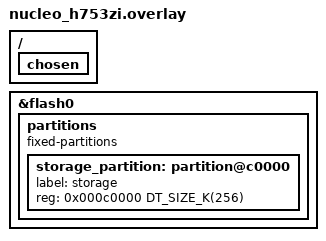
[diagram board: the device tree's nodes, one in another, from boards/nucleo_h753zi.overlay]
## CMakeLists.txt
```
# SPDX-License-Identifier: Apache-2.0 Copyright 2026 Migris Labs

cmake_minimum_required(VERSION 3.20.0)

find_package(Zephyr REQUIRED HINTS $ENV{ZEPHYR_BASE})
project(fsw_core_tc_uart LANGUAGES C)

# Pull in the freestanding PUS codec from lib/pus/. Same translation units the host C++ build links
# into migris::fsw-core — keeping the wire-format bytes identical between flight and host tests is
# the whole point of the layout.
set(MIGRIS_FSW_PUS_DIR ${CMAKE_CURRENT_SOURCE_DIR}/../../lib/pus)
set(MIGRIS_FSW_FDIR_DIR ${CMAKE_CURRENT_SOURCE_DIR}/../../lib/fdir)
set(MIGRIS_FSW_DATAPOOL_DIR ${CMAKE_CURRENT_SOURCE_DIR}/../../lib/datapool)
set(MIGRIS_FSW_SCHEDULE_DIR ${CMAKE_CURRENT_SOURCE_DIR}/../../lib/schedule)
set(MIGRIS_FSW_HKSTORE_DIR ${CMAKE_CURRENT_SOURCE_DIR}/../../lib/hkstore)
set(MIGRIS_FSW_PKTSTORE_DIR ${CMAKE_CURRENT_SOURCE_DIR}/../../lib/pktstore)
set(MIGRIS_FSW_LARGEDATA_DIR ${CMAKE_CURRENT_SOURCE_DIR}/../../lib/largedata)
set(MIGRIS_FSW_MODE_DIR ${CMAKE_CURRENT_SOURCE_DIR}/../../lib/mode)
set(MIGRIS_FSW_NVSTORE_DIR ${CMAKE_CURRENT_SOURCE_DIR}/../../lib/nvstore)

target_sources(
  app
  PRIVATE src/main.c
          src/nv_flash_backend.c
          ${MIGRIS_FSW_PUS_DIR}/src/ccsds.c
          ${MIGRIS_FSW_PUS_DIR}/src/pus_tc.c
          ${MIGRIS_FSW_PUS_DIR}/src/pus_tm.c
          ${MIGRIS_FSW_PUS_DIR}/src/pus1.c
          ${MIGRIS_FSW_PUS_DIR}/src/pus5.c
          ${MIGRIS_FSW_PUS_DIR}/src/pus17.c
          ${MIGRIS_FSW_PUS_DIR}/src/pus3.c
          ${MIGRIS_FSW_PUS_DIR}/src/pus11.c
          ${MIGRIS_FSW_PUS_DIR}/src/pus15.c
          ${MIGRIS_FSW_PUS_DIR}/src/pus20.c
          ${MIGRIS_FSW_PUS_DIR}/src/pus13.c
          ${MIGRIS_FSW_PUS_DIR}/src/tc_router.c
          ${MIGRIS_FSW_FDIR_DIR}/src/event_fifo.c
          ${MIGRIS_FSW_FDIR_DIR}/src/fdir.c
          ${MIGRIS_FSW_DATAPOOL_DIR}/src/datapool.c
          ${MIGRIS_FSW_SCHEDULE_DIR}/src/schedule.c
          ${MIGRIS_FSW_HKSTORE_DIR}/src/hkstore.c
          ${MIGRIS_FSW_PKTSTORE_DIR}/src/pktstore.c
          ${MIGRIS_FSW_LARGEDATA_DIR}/src/largedata.c
          ${MIGRIS_FSW_MODE_DIR}/src/mode.c
          ${MIGRIS_FSW_NVSTORE_DIR}/src/nvstore.c)

target_include_directories(app PRIVATE ${MIGRIS_FSW_PUS_DIR}/include
                                       ${MIGRIS_FSW_FDIR_DIR}/include
                                       ${MIGRIS_FSW_DATAPOOL_DIR}/include
                                       ${MIGRIS_FSW_SCHEDULE_DIR}/include
                                       ${MIGRIS_FSW_HKSTORE_DIR}/include
                                       ${MIGRIS_FSW_PKTSTORE_DIR}/include
                                       ${MIGRIS_FSW_LARGEDATA_DIR}/include
                                       ${MIGRIS_FSW_MODE_DIR}/include
                                       ${MIGRIS_FSW_NVSTORE_DIR}/include)

# Size the freestanding event FIFO, the parameter datapool, the
# schedule store, the packet store, and the PUS-20 / PUS-11 per-TC
# bounds from Kconfig. Applied to the whole `app` target (every lib TU
# above is part of it) so the struct sizes are identical across all
# sample TUs; the host library build has no such defines and uses the
# lib defaults.
target_compile_definitions(
  app
  PRIVATE MIGRIS_FDIR_EVENT_FIFO_CAPACITY=${CONFIG_FSW_FDIR_EVENT_FIFO_CAPACITY}
          MIGRIS_DATAPOOL_CAPACITY=${CONFIG_FSW_DATAPOOL_CAPACITY}
          MIGRIS_PUS20_MAX_PARAMS_PER_TC=${CONFIG_FSW_PUS20_MAX_PARAMS}
          MIGRIS_SCHEDULE_CAPACITY=${CONFIG_FSW_SCHEDULE_CAPACITY}
          MIGRIS_SCHEDULE_TC_MAX=${CONFIG_FSW_SCHEDULE_TC_MAX}
          MIGRIS_HKSTORE_CAPACITY=${CONFIG_FSW_HKSTORE_CAPACITY}
          MIGRIS_HKSTORE_MAX_PARAMS=${CONFIG_FSW_HKSTORE_MAX_PARAMS}
          MIGRIS_PUS11_MAX_PER_TC=${CONFIG_FSW_PUS11_MAX_PER_TC}
          MIGRIS_PKTSTORE_CAPACITY=${CONFIG_FSW_PKTSTORE_CAPACITY}
          MIGRIS_PKTSTORE_PACKET_MAX=${CONFIG_FSW_PKTSTORE_PACKET_MAX}
          MIGRIS_MODE_CAPACITY=${CONFIG_FSW_MODE_CAPACITY})
```

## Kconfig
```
# SPDX-License-Identifier: Apache-2.0
# Copyright 2026 Migris Labs
#
# Application Kconfig for the tc_uart sample. Zephyr sources the
# application-root Kconfig automatically; `source "Kconfig.zephyr"`
# keeps every base symbol available so prj.conf still works.

source "Kconfig.zephyr"

config FSW_PUS3_HK_PERIOD_SEC
	int "PUS-3 housekeeping report period (seconds)"
	default 5
	range 1 86400
	help
	  Initial value of datapool parameter 0x0001 — the interval between
	  spontaneous PUS-3[25] housekeeping parameter reports emitted by
	  the main loop. The cadence is a coarse main-loop elapsed-time
	  check against the FSW clock (k_uptime_get()/1000), not a kernel
	  timer. As of slice fsw-9 the period is a live-tunable datapool
	  parameter: a PUS-20[3] set retunes the cadence with no rebuild,
	  and a value of 0 disables periodic housekeeping. This symbol only
	  seeds the initial value. The default (5 s) is operationally sane.
	  The Renode closed-loop suite builds two
	  artefacts from this one sample: the verification-stream ELF pins
	  this to 86400 (effectively "never within a test" — Renode
	  fast-forwards idle virtual time, so a fixed short period would
	  race the fixed-offset reads non-deterministically), and a
	  dedicated housekeeping ELF pins it to 2 s for fast, deterministic
	  cadence assertions.

config FSW_FDIR_EVENT_FIFO_CAPACITY
	int "FDIR event FIFO capacity (records)"
	default 16
	range 4 256
	help
	  Number of records the bounded FDIR event FIFO holds before it
	  starts dropping the newest (the causal head — the first faults —
	  is preserved). Wired into the freestanding lib via the
	  MIGRIS_FDIR_EVENT_FIFO_CAPACITY compile definition so flight and
	  host builds size the ring identically. The default (16) absorbs a
	  burst of rejected TCs plus RX-overflow events between main-loop
	  drains; raise it only if a producer can outpace one drain per
	  loop iteration.

config FSW_DATAPOOL_CAPACITY
	int "Parameter datapool capacity (parameters)"
	default 8
	range 1 256
	help
	  Number of parameters the on-board datapool can hold. Wired into
	  the freestanding lib via the MIGRIS_DATAPOOL_CAPACITY compile
	  definition so flight and host builds size the store identically.
	  This sample registers a single parameter (the housekeeping
	  period); the default (8) leaves room for a mission to add more.

config FSW_PUS20_MAX_PARAMS
	int "PUS-20 maximum parameters per TC"
	default 8
	range 1 8
	help
	  Upper bound on the parameters one PUS-20 TC may address and one
	  [20,2] report may carry. Wired into the freestanding lib via the
	  MIGRIS_PUS20_MAX_PARAMS_PER_TC compile definition; it bounds the
	  worst-case [20,2] packet. Capped at 8 here because the TC router
	  output buffer (MIGRIS_TC_ROUTER_MAX_TM, a fixed 128) is sized for
	  that worst case — a larger value needs that constant raised too.

config FSW_SCHEDULE_CAPACITY
	int "On-board schedule capacity (activities)"
	default 16
	range 1 256
	help
	  Number of time-tagged telecommands the on-board schedule can
	  hold. Wired into the freestanding lib via the
	  MIGRIS_SCHEDULE_CAPACITY compile definition so flight and host
	  builds size the store identically.

config FSW_SCHEDULE_TC_MAX
	int "On-board schedule per-activity TC size (bytes)"
	default 64
	range 16 256
	help
	  Largest telecommand, in bytes, that one scheduled activity can
	  hold. Wired into the freestanding lib via the
	  MIGRIS_SCHEDULE_TC_MAX compile definition. 64 covers the
	  PUS-17 / PUS-20-class leaf commands of the baseline; a PUS-11
	  insert carrying a larger telecommand is rejected.

config FSW_HKSTORE_CAPACITY
	int "On-board housekeeping-structure store capacity (structures)"
	default 8
	range 1 256
	help
	  Number of ground-defined PUS-3 housekeeping structures the
	  on-board store can hold. Wired into the freestanding lib via the
	  MIGRIS_HKSTORE_CAPACITY compile definition so flight and host
	  builds size the store identically. The store is RAM-backed and
	  volatile — empty after every reboot.

config FSW_HKSTORE_MAX_PARAMS
	int "Housekeeping structure maximum parameters"
	default 8
	range 1 16
	help
	  Upper bound on the datapool parameters one housekeeping structure
	  may sample, and so on the worst-case dynamic PUS-3[25] report.
	  Wired into the freestanding lib via the MIGRIS_HKSTORE_MAX_PARAMS
	  compile definition. Capped at 16 because a [3,27] poll wraps the
	  report in a PUS-1 acceptance + completion burst that must fit the
	  fixed 128-byte TC router output buffer (MIGRIS_TC_ROUTER_MAX_TM):
	  22 + (6 + 10 + 2 + 4*16 + 2) + 22 = 128.

config FSW_PUS11_MAX_PER_TC
	int "PUS-11 maximum activities per TC"
	default 8
	range 1 8
	help
	  Upper bound on the activities one PUS-11 insert / delete / report
	  TC may carry, and one [11,12] summary report may list. Wired into
	  the freestanding lib via the MIGRIS_PUS11_MAX_PER_TC compile
	  definition; it bounds the worst-case [11,12] packet. Capped at 8
	  here because the TC router output buffer (MIGRIS_TC_ROUTER_MAX_TM,
	  a fixed 128) is sized for that worst case.

config FSW_PKTSTORE_CAPACITY
	int "On-board packet store capacity (packets)"
	default 32
	range 4 256
	help
	  Number of telemetry packets the on-board packet store can hold
	  before it overwrites the oldest. Wired into the freestanding lib
	  via the MIGRIS_PKTSTORE_CAPACITY compile definition so flight and
	  host builds size the store identically. The store is RAM-backed
	  and volatile — it is empty after every reboot. Storage is
	  CAPACITY x (PACKET_MAX + a little overhead) bytes of BSS; the
	  default (32) is a few KB on the H7 and absorbs a pass's worth of
	  housekeeping plus verification telemetry.

config FSW_PKTSTORE_PACKET_MAX
	int "On-board packet store per-packet size (bytes)"
	default 128
	range 80 128
	help
	  Largest telemetry packet, in bytes, one packet-store entry can
	  hold. Wired into the freestanding lib via the
	  MIGRIS_PKTSTORE_PACKET_MAX compile definition. A larger packet is
	  refused by migris_pktstore_store and skipped by the transmit_tm
	  tap. Capped at 128 because the retrieval drain re-emits a stored
	  packet through the shared 128-byte router output buffer
	  (MIGRIS_TC_ROUTER_MAX_TM); the floor (80) stays clear of the
	  largest baseline TM packet (a PUS-20[2] value report).

config FSW_LARGEDATA_DEMO
	bool "Run a PUS-13 large-data downlink demo at boot"
	default n
	help
	  When set, the tc_uart sample starts one PUS-13 large-data
	  transfer at boot: a synthetic data unit is downlinked as an
	  ordered sequence of [13,1] / [13,2] / [13,3] part packets, one
	  part per main-loop iteration. PUS-13 (lib/pus/pus13.{h,c} +
	  lib/largedata/) has no inbound telecommand, so a closed-loop
	  test cannot trigger a transfer the way it triggers PUS-11 or
	  PUS-15 — the demo is the observable surface for the reassembly
	  closed-loop in tests/renode/test_tc_uart_hk.py. Left off by
	  default: the verification-stream ELF (test_tc_uart.py) reads a
	  fixed byte count per stimulus and must not see unsolicited
	  large-data telemetry. The Renode housekeeping build turns it on.

config FSW_MODE_DEMO
	bool "Run an operating-mode-manager demo at boot"
	default n
	help
	  When set, the tc_uart sample wires an operating-mode manager and
	  performs one demo transition at boot (BOOT -> NOMINAL); the mode
	  manager announces it as a spontaneous PUS-5 MODE_CHANGED event.
	  The mode manager (lib/mode/) has no inbound telecommand — a
	  ground mode-commanding service is downstream (cry4-fsw) — so the
	  demo is the observable surface for the closed-loop test in
	  tests/renode/test_tc_uart_hk.py. Left off by default for the
	  same reason as FSW_LARGEDATA_DEMO: the verification-stream ELF
	  reads a fixed byte count per stimulus. The housekeeping build
	  turns it on.

config FSW_MODE_CAPACITY
	int "Operating-mode manager capacity (modes)"
	default 8
	range 2 32
	help
	  Number of distinct operating modes the on-board mode manager can
	  hold. Wired into the freestanding lib via the MIGRIS_MODE_CAPACITY
	  compile definition so flight and host builds size the manager
	  identically. This sample defines three modes (boot, nominal,
	  safe); the default (8) leaves room for a mission to add more.
	  Capped at 32 — a mode ID must fit the allowed-target bitmask.

config FSW_FDIR_RECOVERY_DEMO
	bool "Arm FDIR autonomous recovery to SAFE mode"
	depends on FSW_MODE_DEMO
	default n
	help
	  When set, the tc_uart sample arms FDIR isolation/recovery: after
	  CONFIG_FSW_FDIR_TC_REJECTED_THRESHOLD rejected telecommands FDIR
	  confirms the fault, emits a high-severity PUS-5 FDIR_RECOVERY
	  event, and autonomously commands the mode manager to SAFE. Left
	  off by default — the verification-stream ELF (test_tc_uart.py)
	  reads a fixed byte count per stimulus and must not see the extra
	  recovery telemetry. The Renode housekeeping build turns it on for
	  the closed-loop in test_tc_uart_hk.py. Depends on FSW_MODE_DEMO:
	  recovery needs the mode manager as its transition target.

config FSW_FDIR_TC_REJECTED_THRESHOLD
	int "Rejected-telecommand occurrences that confirm the fault"
	depends on FSW_FDIR_RECOVERY_DEMO
	default 3
	range 1 65535
	help
	  Number of rejected telecommands FDIR counts before it confirms a
	  TC_REJECTED fault and triggers autonomous recovery. A single
	  transient rejection must never safe the spacecraft — this is the
	  debounce count.
```

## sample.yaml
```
sample:
  name: fsw-core TC reception + verification
  description: >-
    Zephyr application that listens on USART3 for a CCSDS Space
    Packet, runs it through the TC router (PUS-1 verification +
    PUS-17 / PUS-3 / PUS-20 / PUS-11 service routing), and writes
    the resulting TM stream back on the same UART. Carries an
    on-board parameter datapool (PUS-3 housekeeping period
    live-tunable via PUS-20) and an on-board schedule (PUS-11
    time-tagged telecommands released autonomously). Used by the
    Renode round-trip smoke test in tests/renode/.
tests:
  sample.fsw-core.tc_uart:
    platform_allow: nucleo_h753zi
    tags: pus uart
    # The sample only emits when a TC arrives — there is no
    # spontaneous output to harness on. Twister discovery lives
    # here so the build is exercised; behavioural coverage is
    # provided by tests/renode/test_tc_uart.py.
    harness: none
```

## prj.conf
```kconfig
# Minimum Zephyr configuration for the fsw-5 TC-router UART sample.
#
# We own USART3 end-to-end for the packet exchange: no boot banner,
# no log backend, no console printk competing for the same wire.
# Anything that prints would corrupt the packet stream the ground
# tooling is reading byte-exact off the UART.

CONFIG_BOOT_BANNER=n
CONFIG_LOG=n
CONFIG_PRINTK=n
CONFIG_UART_CONSOLE=n

CONFIG_SERIAL=y
CONFIG_UART_INTERRUPT_DRIVEN=y
CONFIG_RING_BUFFER=y

CONFIG_THREAD_NAME=y
# fsw-9 added the parameter datapool (a main()-local), larger TC/TM
# buffers, and the PUS-20 dispatch call chain; 2048 keeps comfortable
# headroom over the deepest path.
CONFIG_MAIN_STACK_SIZE=2048

# fsw-16: on-chip flash + the flash_map partition layer for the
# non-volatile parameter store. The board devicetree defines a 256 KB
# storage_partition (two 128 KB sectors); CONFIG_FLASH_MAP gives us the
# flash_area_* API over it. CONFIG_SOC_FLASH_STM32 enables the in-tree
# STM32H7 flash driver (drivers/flash/flash_stm32h7x.c). NVS is *not*
# usable on STM32H7 — the 128 KB sector overflows NVS's uint16_t
# sector_size — so we use the raw flash_area_* API directly.
CONFIG_FLASH=y
CONFIG_FLASH_MAP=y
CONFIG_SOC_FLASH_STM32=y
```

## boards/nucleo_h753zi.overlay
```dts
/*
 * SPDX-License-Identifier: Apache-2.0
 * Copyright 2026 Migris Labs
 *
 * Devicetree overlay for slice fsw-16: expand `storage_partition` from
 * the Zephyr v3.7.1 default of one 128 KB sector to two 128 KB sectors
 * (256 KB total) so `lib/nvstore/` has room for its power-safe A/B
 * ping-pong. The two sectors land at the top of flash bank 1
 * (offsets 0xC0000 and 0xE0000), reclaiming the default mcuboot /
 * image-0 / image-1 / image-scratch slots — this sample does not use
 * MCUboot or image slots, so dropping them is fine.
 *
 * The board's default `chosen.zephyr,code-partition` references
 * `&slot0_partition`, which the new partition table no longer
 * provides; the property is deleted so the FSW links to flash base
 * (the default for boards without MCUboot).
 */

/ {
	chosen {
		/delete-property/ zephyr,code-partition;
	};
};

&flash0 {
	/delete-node/ partitions;

	partitions {
		compatible = "fixed-partitions";
		#address-cells = <1>;
		#size-cells = <1>;

		storage_partition: partition@c0000 {
			label = "storage";
			reg = <0x000c0000 DT_SIZE_K(256)>;
		};
	};
};
```

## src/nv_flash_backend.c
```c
/*
 * SPDX-License-Identifier: Apache-2.0
 * Copyright 2026 Migris Labs
 *
 * Zephyr `flash_area_*` backend for `lib/nvstore/`. Slice fsw-16.
 *
 * The board's `storage_partition` (defined in
 * `boards/st/nucleo_h753zi/nucleo_h753zi.dts`: 256 KB at offset
 * 0xC0000 = exactly two of the STM32H7's 128 KB flash sectors)
 * becomes the A/B ping-pong NVM. `flash_area_get_sectors` is the
 * authoritative source for the actual sector size at boot;
 * `flash_area_align` returns the per-write alignment the STM32H7
 * driver enforces (32 bytes on the H7).
 *
 * One static partition handle is enough for the sample (single
 * application process); the `self` arg of the backend vtable is left
 * unused.
 */

#include "nv_flash_backend.h"

#include <stddef.h>
#include <stdint.h>
#include <zephyr/storage/flash_map.h>

#define NV_FLASH_PARTITION FIXED_PARTITION_ID(storage_partition)

/* Set by ``migris_fsw_nv_flash_backend`` on first use. NULL if
 * `flash_area_open` failed — the stub read/write/erase below then
 * return -1 and the nvstore's load/save fail gracefully. */
static const struct flash_area* nv_flash_area;
/* Resolved at open-time from `flash_area_get_sectors`. The nvstore's
 * sector-indexed API needs to know the actual erase-block size to
 * translate (sector, offset) into a partition offset. */
static uint32_t nv_flash_sector_size;

static int nv_flash_read(void* self, uint32_t sector, uint32_t off, void* dst, size_t len) {
    (void)self;
    if (nv_flash_area == NULL) {
        return -1;
    }
    const off_t partition_off =
        (off_t)((uint64_t)sector * (uint64_t)nv_flash_sector_size) + (off_t)off;
    return flash_area_read(nv_flash_area, partition_off, dst, len);
}

static int nv_flash_write(void* self, uint32_t sector, uint32_t off, const void* src, size_t len) {
    (void)self;
    if (nv_flash_area == NULL) {
        return -1;
    }
    const off_t partition_off =
        (off_t)((uint64_t)sector * (uint64_t)nv_flash_sector_size) + (off_t)off;
    return flash_area_write(nv_flash_area, partition_off, src, len);
}

static int nv_flash_erase(void* self, uint32_t sector) {
    (void)self;
    if (nv_flash_area == NULL) {
        return -1;
    }
    const off_t partition_off = (off_t)((uint64_t)sector * (uint64_t)nv_flash_sector_size);
    return flash_area_erase(nv_flash_area, partition_off, nv_flash_sector_size);
}

migris_nv_backend_t migris_fsw_nv_flash_backend(void) {
    migris_nv_backend_t bk;
    bk.read = nv_flash_read;
    bk.write = nv_flash_write;
    bk.erase = nv_flash_erase;
    bk.sector_size = 0U;
    bk.sector_count = 0U;
    bk.write_block = 0U;
    bk.self = NULL;

    /* Open the partition and discover the actual sector geometry. We
     * use only the first two sectors (A/B ping-pong); any extra sectors
     * the partition might hold are reserved for future slices. */
    if (flash_area_open(NV_FLASH_PARTITION, &nv_flash_area) != 0) {
        nv_flash_area = NULL;
        return bk;
    }
    struct flash_sector sectors[2];
    uint32_t count = 2U;
    if (flash_area_get_sectors(NV_FLASH_PARTITION, &count, sectors) != 0 || count < 2U) {
        flash_area_close(nv_flash_area);
        nv_flash_area = NULL;
        return bk;
    }
    nv_flash_sector_size = (uint32_t)sectors[0].fs_size;

    bk.sector_size = nv_flash_sector_size;
    bk.sector_count = 2U;
    bk.write_block = (uint32_t)flash_area_align(nv_flash_area);
    return bk;
}
```

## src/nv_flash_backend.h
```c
/*
 * SPDX-License-Identifier: Apache-2.0
 * Copyright 2026 Migris Labs
 *
 * Zephyr `flash_area_*` backend for the freestanding `lib/nvstore/`
 * layer. Slice fsw-16. Sample-local glue: the board's
 * `storage_partition` (256 KB on `nucleo_h753zi`, two 128 KB sectors)
 * becomes the A/B ping-pong NVM the nvstore manages.
 *
 * This file lives in the sample because it is the Zephyr-specific
 * side of the seam — `lib/nvstore/` itself is freestanding C. A
 * future HAL/BSP slice may promote it to a reusable component.
 */

#ifndef MIGRIS_FSW_TC_UART_NV_FLASH_BACKEND_H_
#define MIGRIS_FSW_TC_UART_NV_FLASH_BACKEND_H_

#include "migris/fsw/nvstore/nvstore.h"

#ifdef __cplusplus
extern "C" {
#endif

/** Build a `migris_nv_backend_t` that wraps Zephyr's `flash_area_*`
 *  API over the board's `storage_partition`. Returns a backend ready
 *  to hand to `migris_nvstore_init`. On failure (the flash driver did
 *  not initialise, the devicetree partition is missing, or the
 *  partition does not have at least two sectors) every function
 *  pointer is left wired to a stub that returns ``-1``, so the
 *  nvstore's `load`/`save` will fail cleanly without crashing. */
migris_nv_backend_t migris_fsw_nv_flash_backend(void);

#ifdef __cplusplus
}
#endif

#endif  // MIGRIS_FSW_TC_UART_NV_FLASH_BACKEND_H_
```
